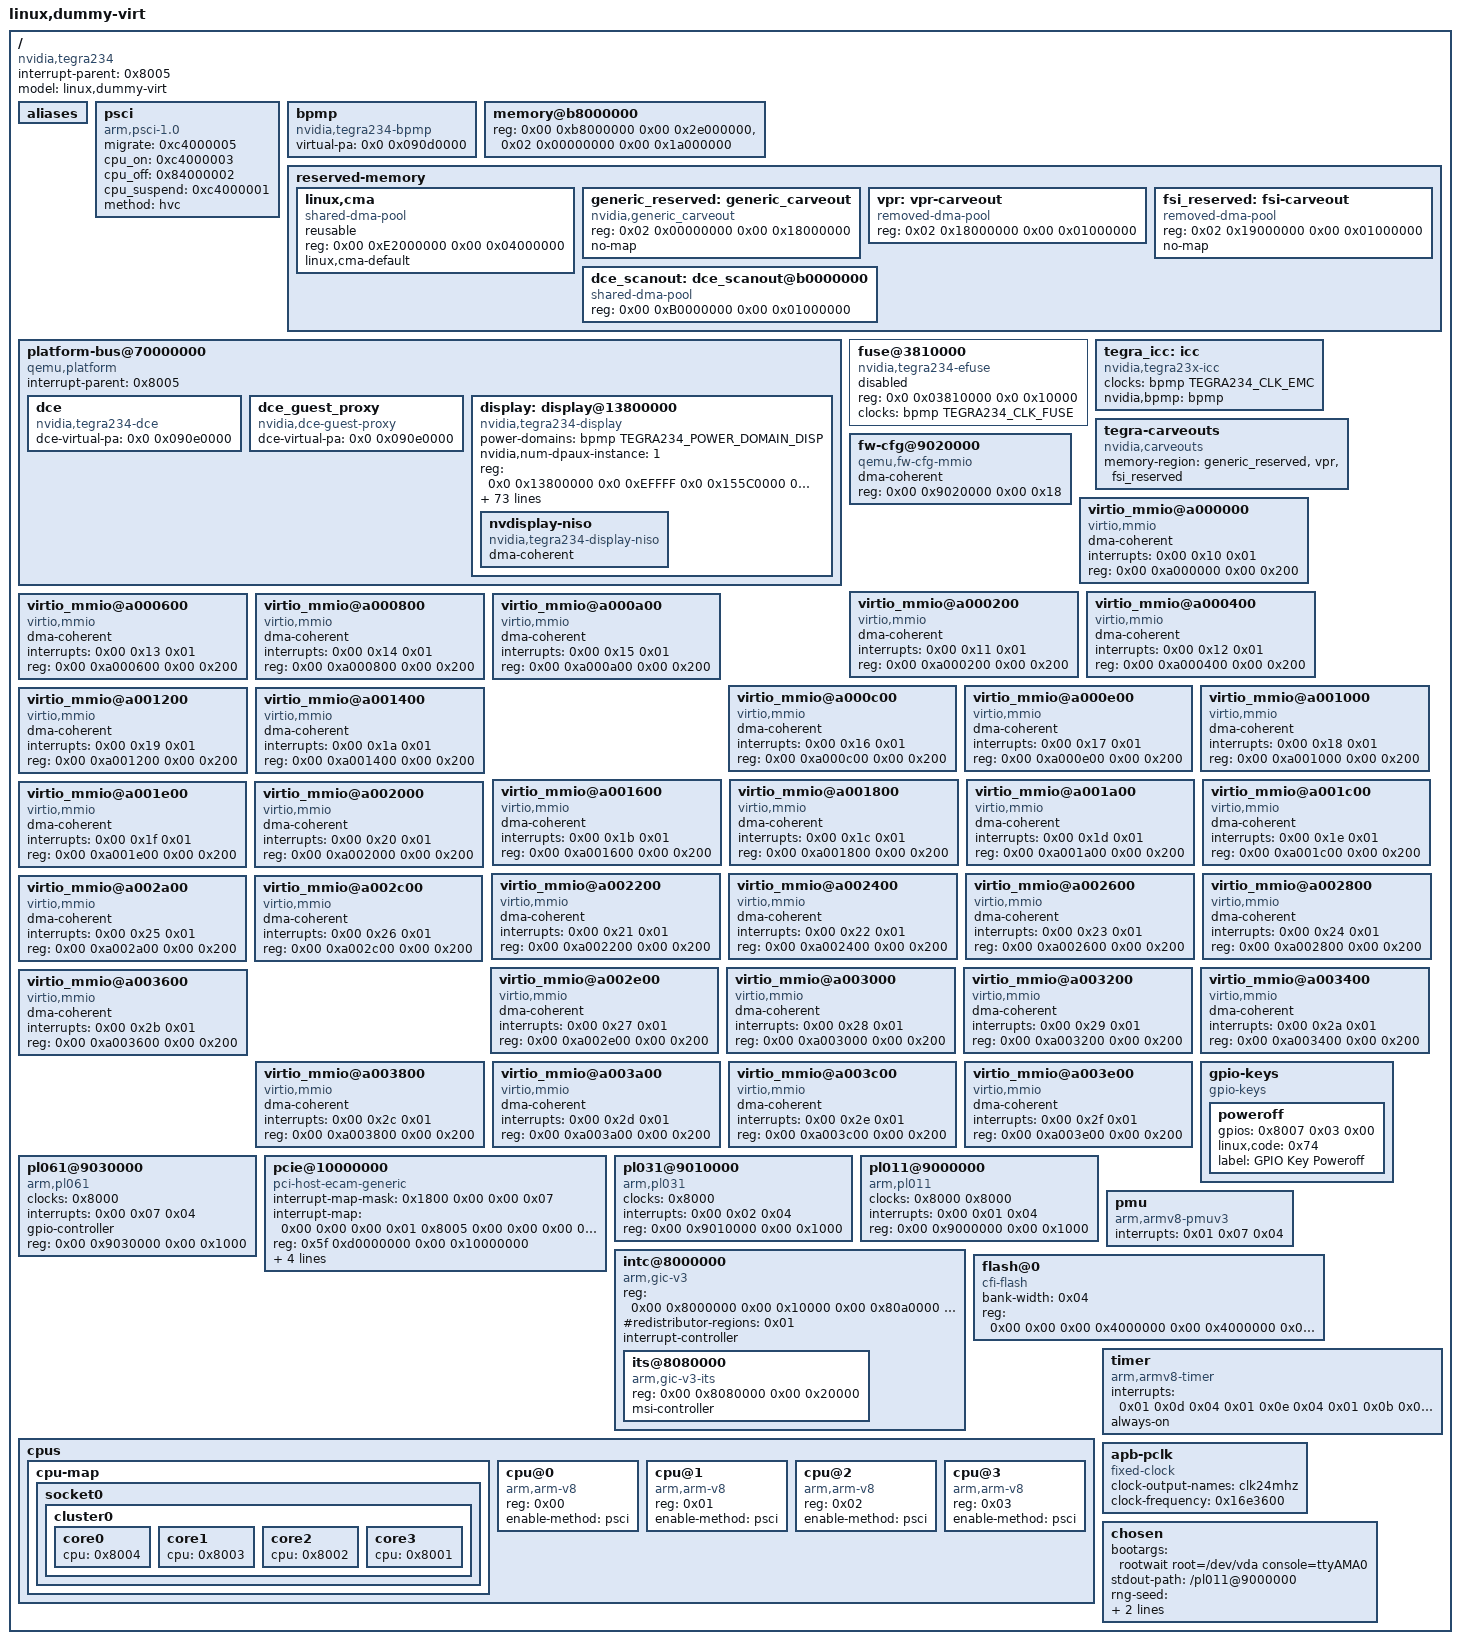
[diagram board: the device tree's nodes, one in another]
// SPDX-License-Identifier: GPL-2.0-only
// SPDX-FileCopyrightText: Copyright (c) 2023, NVIDIA CORPORATION & AFFILIATES.  All rights reserved.
//
// disp-vm guest DTS: display-only, no host1x, no gpu. Companion to
// tegra234-gpuvm.dts (compute-with-host1x mode) for the concurrent two-VM
// build (experiment/orin-two-vm-host1x). Owns exactly 3 physical devices
// (scanout_p, disp_caps_pt, disp_chan_pt), all already declared+reserved by
// gpu_passthrough_overlay.dts. Unlike the GPU VM, general guest RAM
// (memory@80000000) is plain QEMU -m emulated RAM -- no vm_cma_p carveout is
// claimed here, so there is no host-PA collision with the GPU VM's own
// bank1 at the same GPA range (each QEMU process has its own guest-physical
// address space). Only the scanout carveout is a real 1:1 GPA=HPA mapping.

#include <dt-bindings/clock/tegra234-clock.h>
#include <dt-bindings/reset/tegra234-reset.h>
#include <dt-bindings/mailbox/tegra186-hsp.h>
#include <dt-bindings/memory/tegra234-mc.h>
#include <dt-bindings/interrupt-controller/irq.h>
#include <dt-bindings/interrupt-controller/arm-gic.h>
#include <dt-bindings/interrupt/tegra234-irq.h>
#include <dt-bindings/gpio/tegra234-gpio.h>
#include <dt-bindings/p2u/tegra234-p2u.h>
#include <dt-bindings/power/tegra234-powergate.h>
#include <dt-bindings/pinctrl/pinctrl-tegra.h>

/dts-v1/;


/ {
	interrupt-parent = <0x8005>;
	model = "linux,dummy-virt";
	#size-cells = <0x02>;
	#address-cells = <0x02>;

	// Some drivers need that the root node has this compatible property
	compatible = "nvidia,tegra234";

	// No host1x alias: disp-vm never claims physical host1x (that stays
	// with the GPU VM as host1x owner).
	aliases {
	};

	psci {
		migrate = <0xc4000005>;
		cpu_on = <0xc4000003>;
		cpu_off = <0x84000002>;
		cpu_suspend = <0xc4000001>;
		method = "hvc";
		compatible = "arm,psci-1.0\0arm,psci-0.2\0arm,psci";
	};

	bpmp: bpmp {
		compatible = "nvidia,tegra234-bpmp", "nvidia,tegra186-bpmp";
		// Must match QEMU's VIRT_NVIDIA_BPMP_GUEST base (hw/arm/virt.c).
		virtual-pa = <0x0 0x090d0000>;
		#clock-cells = <1>;
		#reset-cells = <1>;
		#power-domain-cells = <1>;
		status = "okay";
	};

	// Plain QEMU -m emulated RAM (no 1:1 host carveout backs this bank):
	// bank1 only, 0x80000000..0xb0000000 (768MB). No GPU VRAM bank2 (no
	// GPU here). The scanout carveout at 0xb0000000 (below) is a SEPARATE
	// 1:1 vfio mapping, outside this bank.
	// disp-vm guest RAM = 1:1 GPA=HPA carveout (dispram_p@0x200000000, 1.125GB),
	// exactly like gpu-vm's vm_cma. QEMU -m does not reliably back the guest in
	// this tegra passthrough setup (the virt -m base != the DTB memory@), so RAM
	// comes from a real reserved host carveout mapped 1:1 via vfio mmio-base.
	// 0xb8000000..0x100000000 sits between disp-vm's scanout (0xb0..0xb8) and
	// gpu-vm's vram (0x100000000+), disjoint from every gpu-vm carveout.
	// Split RAM: LOW bank (0xb8000000..0xe6000000, 736MB = 672MB normal + 64MB CMA)
	// holds the kernel/initrd + working set. HIGH bank (0x200000000..0x21a000000,
	// 416MB) holds the GPU-style carveouts (generic/vpr/fsi), keeping the low bank
	// at the proven 672MB normal RAM. DMA32 hole 0xe6000000..0x100000000 left to
	// the host for PCIe MSI / WLAN.
	memory@b8000000 {
		reg = <0x00 0xb8000000 0x00 0x2e000000>,
		      <0x02 0x00000000 0x00 0x1a000000>;
		device_type = "memory";
	};

	reserved-memory {
		#address-cells = <2>;
		#size-cells = <2>;
		ranges;

		// All carveouts RELOCATED into disp-vm's backed RAM (dispram
		// 0xb8000000..0x100000000). The old 0x8x addresses were gpu-vm's bank1
		// region (0x80..0xb0) -- unbacked for disp-vm and overlapping the GPU
		// VM. Here they sit in disp-vm's own carveout RAM, leaving 0xb8000000..
		// carveouts live in the high dispram RAM (0x200000000..0x248000000),
		// leaving 0x200000000..0x220000000 (512MB) free kernel RAM (swiotlb fits)
		// + a 160MB tail. All backed by dispram_p; below-4GB DMA32 host RAM is
		// left untouched so PCIe MSI works.
		// CMA in the LOW bank (backed, cma-default) for dumb buffers.
		linux,cma {
			compatible = "shared-dma-pool";
			reusable;
			reg = <0x00 0xE2000000 0x00 0x04000000>; // 64MB @ 0xe2000000 (low bank top)
			linux,cma-default;
			status = "okay";
		};

		// GPU-style carveouts in the HIGH bank (0x200000000..0x21a000000).
		generic_reserved: generic_carveout {
			compatible = "nvidia,generic_carveout";
			reg = <0x02 0x00000000 0x00 0x18000000>; // 384MB @ 0x200000000..0x218000000
			no-map;
			status = "okay";
		};

		vpr: vpr-carveout {
			compatible = "removed-dma-pool";
			reg = <0x02 0x18000000 0x00 0x01000000>; // 16MB @ 0x218000000
			status = "okay";
		};

		fsi_reserved: fsi-carveout {
			compatible = "removed-dma-pool";
			reg = <0x02 0x19000000 0x00 0x01000000>; // 16MB @ 0x219000000
			no-map;
			status = "okay";
		};

		// 1:1 GPA=HPA scanout carveout. nvdisplay allocates the scanout
		// surface here; the host-owned DCE R5 DMAs it at the same
		// physical address. Backed 1:1 by scanout_p in
		// gpu_passthrough_overlay.dts (host removed-dma-pool + vfio
		// mmio-base=0xb0000000, already declared for the GPU VM and
		// reused here -- disp-vm is the sole owner in compute-with-host1x
		// mode, where the GPU VM drops its own scanout claim).
		// NOTE: sits OUTSIDE the memory@ bank1 above (which ends exactly
		// at 0xb0000000) -- validated on hardware as a follow-up gate
		// (Step 2 is build-only; see task handoff).
		dce_scanout: dce_scanout@b0000000 {
			// NOT reusable: this carveout is OUTSIDE every guest RAM bank
			// (bank1 ends exactly at 0xb0000000). "reusable" would make it CMA,
			// and cma_init_reserved_areas walks pfn_valid(0xb0000) -> faults on
			// out-of-System-RAM pages -> deterministic early kill-init. Plain
			// shared-dma-pool = dedicated coherent DMA pool (no CMA pfn walk);
			// dma_alloc_coherent still returns 0xb0000000-range scanout addrs.
			compatible = "shared-dma-pool";
			reg = <0x00 0xB0000000 0x00 0x01000000>; // 16MB (rest unclaimed)
			status = "okay";
		};
	};


	platform-bus@70000000 {
		interrupt-parent = <0x8005>;

		// QEMU does not map 1:1 the platform devices, so we have to define
		// the address translation here. Only display + dce need it (no
		// gpu/host1x/vic/nvdec/nvjpg on this VM).
		ranges = <0x00 0x13800000 0x00 0x66200000 0x00 0x000EFFFF>,     // display region 0
			 <0x00 0x155C0000 0x00 0x660e0000 0x00 0x0000FFFF>,     // display region 1 (dpaux0)
			 <0x00 0x0242c000 0x00 0x66001000 0x00 0x00001000>,     // display region 2 (hdacodec)
			 <0x00 0x03990000 0x00 0x660f0000 0x00 0x00010000>,     // display region 3 (mipical)
			 <0x00 0x0d800000 0x00 0x66800000 0x00 0x00800000>;     // dce region 0

		#address-cells = <0x02>;
		#size-cells = <0x02>;
		compatible = "qemu,platform\0simple-bus";

		dce {
			compatible = "nvidia,tegra234-dce";
			dce-virtual-pa = <0x0 0x090e0000>;
			status = "okay";
		};

		// The dce-guest-proxy .ko binds this node, ioremaps dce-virtual-pa
		// and installs tegra_dce_ipc_send_redirect so tegra-dce's client
		// sends are relayed through the shared window to the host DCE.
		dce_guest_proxy {
			compatible = "nvidia,dce-guest-proxy";
			dce-virtual-pa = <0x0 0x090e0000>;
			status = "okay";
		};
		display: display@13800000 {
			compatible = "nvidia,tegra234-display";
			power-domains = <&bpmp TEGRA234_POWER_DOMAIN_DISP>;
			nvidia,num-dpaux-instance = <1>;
			reg-names = "nvdisplay", "dpaux0", "hdacodec", "mipical";
			reg = <0x0 0x13800000 0x0 0xEFFFF    /* nvdisplay */
				0x0 0x155C0000 0x0 0xFFFF     /* dpaux0 */
				0x0 0x0242c000 0x0 0x1000     /* hdacodec */
				0x0 0x03990000 0x0 0x10000>;  /* mipical */
			interrupt-names = "nvdisplay", "dpaux0", "hdacodec";
			interrupts = <0 128 4
				0 129 4
				0 130 4>;
			nvidia,bpmp = <&bpmp>;
			clocks = <&bpmp TEGRA234_CLK_HUB>,
				<&bpmp TEGRA234_CLK_DISP>,
				<&bpmp TEGRA234_CLK_NVDISPLAY_P0>,
				<&bpmp TEGRA234_CLK_NVDISPLAY_P1>,
				<&bpmp TEGRA234_CLK_DPAUX>,
				<&bpmp TEGRA234_CLK_FUSE>,
				<&bpmp TEGRA234_CLK_DSIPLL_VCO>,
				<&bpmp TEGRA234_CLK_DSIPLL_CLKOUTPN>,
				<&bpmp TEGRA234_CLK_DSIPLL_CLKOUTA>,
				<&bpmp TEGRA234_CLK_SPPLL0_VCO>,
				<&bpmp TEGRA234_CLK_SPPLL0_CLKOUTPN>,
				<&bpmp TEGRA234_CLK_SPPLL0_CLKOUTA>,
				<&bpmp TEGRA234_CLK_SPPLL0_CLKOUTB>,
				<&bpmp TEGRA234_CLK_SPPLL0_DIV10>,
				<&bpmp TEGRA234_CLK_SPPLL0_DIV25>,
				<&bpmp TEGRA234_CLK_SPPLL0_DIV27PN>,
				<&bpmp TEGRA234_CLK_SPPLL1_VCO>,
				<&bpmp TEGRA234_CLK_SPPLL1_CLKOUTPN>,
				<&bpmp TEGRA234_CLK_SPPLL1_DIV27PN>,
				<&bpmp TEGRA234_CLK_VPLL0_REF>,
				<&bpmp TEGRA234_CLK_VPLL0>,
				<&bpmp TEGRA234_CLK_VPLL1>,
				<&bpmp TEGRA234_CLK_NVDISPLAY_P0_REF>,
				<&bpmp TEGRA234_CLK_RG0>,
				<&bpmp TEGRA234_CLK_RG1>,
				<&bpmp TEGRA234_CLK_DISPPLL>,
				<&bpmp TEGRA234_CLK_DISPHUBPLL>,
				<&bpmp TEGRA234_CLK_DSI_LP>,
				<&bpmp TEGRA234_CLK_DSI_CORE>,
				<&bpmp TEGRA234_CLK_DSI_PIXEL>,
				<&bpmp TEGRA234_CLK_PRE_SOR0>,
				<&bpmp TEGRA234_CLK_PRE_SOR1>,
				<&bpmp TEGRA234_CLK_DP_LINK_REF>,
				<&bpmp TEGRA234_CLK_SOR_LINKA_INPUT>,
				<&bpmp TEGRA234_CLK_SOR_LINKA_AFIFO>,
				<&bpmp TEGRA234_CLK_SOR_LINKA_AFIFO_M>,
				<&bpmp TEGRA234_CLK_RG0_M>,
				<&bpmp TEGRA234_CLK_RG1_M>,
				<&bpmp TEGRA234_CLK_SOR0_M>,
				<&bpmp TEGRA234_CLK_SOR1_M>,
				<&bpmp TEGRA234_CLK_PLLHUB>,
				<&bpmp TEGRA234_CLK_SOR0>,
				<&bpmp TEGRA234_CLK_SOR1>,
				<&bpmp TEGRA234_CLK_SOR_PAD_INPUT>,
				<&bpmp TEGRA234_CLK_PRE_SF0>,
				<&bpmp TEGRA234_CLK_SF0>,
				<&bpmp TEGRA234_CLK_SF1>,
				<&bpmp TEGRA234_CLK_DSI_PAD_INPUT>,
				<&bpmp TEGRA234_CLK_PRE_SOR0_REF>,
				<&bpmp TEGRA234_CLK_PRE_SOR1_REF>,
				<&bpmp TEGRA234_CLK_SOR0_PLL_REF>,
				<&bpmp TEGRA234_CLK_SOR1_PLL_REF>,
				<&bpmp TEGRA234_CLK_SOR0_REF>,
				<&bpmp TEGRA234_CLK_SOR1_REF>,
				<&bpmp TEGRA234_CLK_OSC>,
				<&bpmp TEGRA234_CLK_DSC>,
				<&bpmp TEGRA234_CLK_MAUD>,
				<&bpmp TEGRA234_CLK_AZA_2XBIT>,
				<&bpmp TEGRA234_CLK_AZA_BIT>,
				<&bpmp TEGRA234_CLK_MIPI_CAL>,
				<&bpmp TEGRA234_CLK_UART_FST_MIPI_CAL>,
				<&bpmp TEGRA234_CLK_SOR0_DIV>;
			clock-names = "nvdisplayhub_clk",
				"nvdisplay_disp_clk",
				"nvdisplay_p0_clk",
				"nvdisplay_p1_clk",
				"dpaux0_clk",
				"fuse_clk",
				"dsipll_vco_clk",
				"dsipll_clkoutpn_clk",
				"dsipll_clkouta_clk",
				"sppll0_vco_clk",
				"sppll0_clkoutpn_clk",
				"sppll0_clkouta_clk",
				"sppll0_clkoutb_clk",
				"sppll0_div10_clk",
				"sppll0_div25_clk",
				"sppll0_div27_clk",
				"sppll1_vco_clk",
				"sppll1_clkoutpn_clk",
				"sppll1_div27_clk",
				"vpll0_ref_clk",
				"vpll0_clk",
				"vpll1_clk",
				"nvdisplay_p0_ref_clk",
				"rg0_clk",
				"rg1_clk",
				"disppll_clk",
				"disphubpll_clk",
				"dsi_lp_clk",
				"dsi_core_clk",
				"dsi_pixel_clk",
				"pre_sor0_clk",
				"pre_sor1_clk",
				"dp_link_ref_clk",
				"sor_linka_input_clk",
				"sor_linka_afifo_clk",
				"sor_linka_afifo_m_clk",
				"rg0_m_clk",
				"rg1_m_clk",
				"sor0_m_clk",
				"sor1_m_clk",
				"pllhub_clk",
				"sor0_clk",
				"sor1_clk",
				"sor_pad_input_clk",
				"pre_sf0_clk",
				"sf0_clk",
				"sf1_clk",
				"dsi_pad_input_clk",
				"pre_sor0_ref_clk",
				"pre_sor1_ref_clk",
				"sor0_ref_pll_clk",
				"sor1_ref_pll_clk",
				"sor0_ref_clk",
				"sor1_ref_clk",
				"osc_clk",
				"dsc_clk",
				"maud_clk",
				"aza_2xbit_clk",
				"aza_bit_clk",
				"mipi_cal_clk",
				"uart_fst_mipi_cal_clk",
				"sor0_div_clk";
			resets = <&bpmp TEGRA234_RESET_NVDISPLAY>,
				<&bpmp TEGRA234_RESET_DPAUX>,
				<&bpmp TEGRA234_RESET_DSI_CORE>,
				<&bpmp TEGRA234_RESET_MIPI_CAL>;
			reset-names = "nvdisplay_reset",
				"dpaux0_reset",
				"dsi_core_reset",
				"mipi_cal_reset";
			// hdcp_enabled OMITTED: HDCP handshake invokes the host OP-TEE HDCP/display TA whose supplicant (optee_supp_thrd_req) UAF corrupts the host heap (slub_debug-confirmed); also HPD-glitches DP->HDMI adapters on R36.5.0. Not needed for a plain desktop.
			status = "okay";
			// Scanout surface is allocated from the 1:1 GPA=HPA carveout so
			// the host-owned DCE R5 can DMA it at the same physical address
			// (patch 0003 forces page phys=bus for this device).
			memory-region = <&dce_scanout>;
			nvidia,disp-sw-soc-chip-id = <0x2350>;
	// 		interconnects = <&mc TEGRA234_MEMORY_CLIENT_NVDISPLAYR &emc>,
	// 			      <&mc TEGRA234_MEMORY_CLIENT_NVDISPLAYR1 &emc>;
	// 		interconnect-names = "dma-mem", "read-1";
			//iommus = <&smmu_iso TEGRA234_SID_ISO_NVDISPLAY>;
			non-coherent;

			/* DCB 94.0B.00.00.20 extracted verbatim from the composed host
			 * DTB (tegra234-p3737-0000+p3701-0000-nv.dtb) -- the guest RM
			 * must build display routing from the SAME board topology the
			 * host-owned DCE R5 drives; the previous blob was 94.0B.00.00.21
			 * from a different tree (foreign SOR/connector routing). */
			nvidia,dcb-image = [
				55 aa 16 00 00 37 34 30 30 e9 4c 19 77 cc 56 49
				44 45 4f 20 0d 00 00 00 70 01 00 00 00 00 49 42
				4d 20 56 47 41 20 43 6f 6d 70 61 74 69 62 6c 65
				01 00 00 00 10 00 c7 17 31 30 2f 32 36 2f 32 31
				00 00 00 00 00 00 00 00 21 18 50 00 f1 2a 00 00
				50 4d 49 44 00 00 00 00 00 00 00 a0 00 b0 00 b8
				00 c0 00 0e 47 41 31 30 42 20 56 47 41 20 42 49
				4f 53 0d 0a 00 00 00 00 00 00 00 00 00 00 00 00
				00 00 00 00 00 00 00 00 00 00 00 00 00 00 00 00
				00 00 00 00 00 00 00 00 00 00 00 00 00 00 00 00
				00 00 00 00 00 00 00 00 00 00 00 00 00 00 00 00
				00 00 00 00 00 56 65 72 73 69 6f 6e 20 39 34 2e
				30 42 2e 30 30 2e 30 30 2e 32 30 20 0d 0a 00 43
				6f 70 79 72 69 67 68 74 20 28 43 29 20 31 39 39
				36 2d 32 30 32 31 20 4e 56 49 44 49 41 20 43 6f
				72 70 2e 0d 0a 00 00 00 ff ff 00 00 00 00 ff ff
				47 50 55 20 42 6f 61 72 64 00 00 00 00 00 00 00
				00 00 00 00 00 00 00 00 00 00 00 00 00 00 00 00
				00 00 00 43 68 69 70 20 52 65 76 20 20 20 00 00
				00 00 00 00 00 00 00 ba 91 98 96 91 9a 9a 8d 96
				91 98 df ad 9a 93 9a 9e 8c 9a df d2 df b1 90 8b
				df b9 90 8d df af 8d 90 9b 8a 9c 8b 96 90 91 df
				aa 8c 9a f2 f5 ff 00 00 00 00 00 00 00 00 00 00
				50 43 49 52 de 10 94 22 00 00 18 00 00 00 00 03
				16 00 01 00 00 80 00 00 2e 8b c0 2e 8b c0 8b c0
				4e 50 44 45 01 01 14 00 16 00 00 01 00 00 00 00
				00 00 00 00 00 00 00 00 00 00 00 00 00 00 00 00
				ff b8 42 49 54 00 00 01 0c 06 12 45 32 01 04 00
				38 02 42 02 25 00 44 02 43 02 2c 00 69 02 44 01
				04 00 95 02 49 01 24 00 99 02 4d 02 29 00 bd 02
				4e 00 00 00 00 00 50 02 e8 00 e6 02 53 02 18 00
				ce 03 54 01 02 00 e6 03 55 01 05 00 ec 03 56 01
				06 00 f1 03 78 01 08 00 f7 03 64 01 02 00 ff 03
				70 02 04 00 01 04 75 01 11 00 05 04 69 02 6e 00
				18 04 45 01 04 00 e8 03 00 00 86 04 86 04 fe 20
				00 21 f0 2a 00 00 00 00 00 00 00 00 00 00 00 00
				00 00 00 00 00 00 0b 94 20 00 00 00 00 00 a8 07
				00 00 00 00 00 00 00 00 02 00 5c 5c 28 02 00 00
				3c 02 04 00 10 00 00 00 00 f5 0e 00 00 00 00 00
				00 35 44 00 00 c7 2d 00 00 00 00 00 00 00 00 00
				00 00 00 00 00 72 30 00 00 e1 44 00 00 1f 45 00
				00 46 45 00 00 00 00 00 00 da 04 00 00 00 00 de
				04 00 00 4a 08 de 04 26 2a 4a 08 28 2a 86 04 ef
				09 14 21 d4 09 d7 20 28 2a 90 00 ab 21 01 4c 08
				3a 09 f0 43 00 00 fa 43 00 00 03 10 00 00 00 21
				00 00 0c 21 00 00 50 4a 00 00 00 00 00 00 00 00
				00 00 00 00 00 00 d5 33 00 00 bb 36 00 00 00 00
				00 00 00 00 00 00 00 00 00 00 00 00 00 00 00 00
				00 00 00 00 00 00 af 3c 00 00 00 00 00 00 e9 3c
				00 00 0e 43 00 00 00 00 00 00 00 00 00 00 df 33
				00 00 2e 3d 00 00 9c 43 00 00 ad 36 00 00 00 00
				00 00 00 00 00 00 be 43 00 00 00 00 00 00 00 00
				00 00 00 00 00 00 00 00 00 00 00 00 00 00 45 0b
				00 00 c1 0a 00 00 5b 0b 00 00 11 3c 00 00 17 3c
				00 00 1c 3c 00 00 20 3c 00 00 2a 3c 00 00 31 3c
				00 00 3f 3c 00 00 81 3c 00 00 00 00 00 00 00 00
				00 00 92 3c 00 00 ec 45 00 00 92 47 00 00 07 48
				00 00 8d 49 00 00 7c 4b 00 00 b8 4b 00 00 e2 49
				00 00 98 3c 00 00 79 3c 00 00 00 00 00 00 00 00
				00 00 00 00 00 00 e8 4d 00 00 9c 3c 00 00 a5 3c
				00 00 00 00 00 00 00 00 00 00 00 00 00 00 64 00
				50 b5 00 19 cf 00 28 75 0e 14 89 0e 23 00 01 23
				23 01 14 ac 0e 28 18 11 00 00 00 00 d4 0e 01 00
				00 f1 0d c3 0c 00 00 00 00 01 01 00 00 00 00 f4
				1c 2d 4e 00 00 00 00 00 00 00 00 00 00 00 00 00
				00 00 92 2d 00 00 00 00 00 00 0b 94 20 00 00 20
				92 d2 01 58 03 00 00 31 30 2f 32 36 2f 32 31 00
				00 00 00 00 00 00 00 00 00 00 00 21 01 10 00 00
				00 80 01 00 00 00 00 00 30 30 30 30 30 30 30 30
				30 30 30 30 00 00 00 00 00 00 00 00 03 42 00 00
				b9 78 8f 47 ad 04 4f 3d bf 01 4c 10 55 04 be ee
				54 33 00 00 00 00 00 00 c5 4c 00 00 00 00 00 00
				00 00 93 4e 00 00 01 00 10 00 bf 09 30 00 02 00
				94 22 00 00 00 00 01 00 44 00 6b 09 00 00 86 04
				00 00 3a 09 00 00 de 04 00 00 00 00 00 00 4a 08
				00 00 5c 08 00 00 45 0b 00 00 c1 0a 00 00 5b 0b
				00 00 71 0b 00 00 f1 0d 00 00 c3 0c 00 00 00 00
				00 00 00 00 00 00 00 00 00 00 3c 21 00 00 30 c0
				61 40 00 00 00 10 00 00 00 00 08 23 61 00 80 00
				00 00 80 00 00 00 88 23 61 00 80 00 00 00 80 00
				00 00 08 24 61 00 80 00 00 00 80 00 00 00 88 24
				61 00 80 00 00 00 80 00 00 00 08 25 61 00 80 00
				00 00 80 00 00 00 88 25 61 00 80 00 00 00 80 00
				00 00 08 26 61 00 80 00 00 00 80 00 00 00 00 2a
				13 00 00 00 04 00 00 00 04 00 00 2a 13 00 00 00
				01 00 00 00 01 00 00 6e 13 00 00 00 04 00 00 00
				04 00 00 6e 13 00 00 00 01 00 00 00 01 00 4c 00
				12 00 3f 00 00 00 00 00 00 00 0c 24 02 00 01 00
				00 00 00 00 00 00 e4 05 02 00 7c 00 00 00 00 00
				00 00 e4 05 02 00 7c 00 00 00 18 00 00 00 e4 05
				02 00 7c 00 00 00 0c 00 00 00 e4 05 02 00 7c 00
				00 00 04 00 00 00 e4 05 02 00 7c 00 00 00 08 00
				00 00 e4 05 02 00 7c 00 00 00 14 00 00 00 20 0e
				9a 00 00 00 02 00 00 00 02 00 00 0e 9a 00 00 00
				02 00 00 00 02 00 00 0e 9a 00 01 00 00 00 01 00
				00 00 34 c0 61 40 00 00 00 80 00 00 00 00 00 0c
				82 00 ff ff ff ff 00 00 00 00 00 0c 82 00 01 00
				00 00 00 00 00 00 00 0c 82 00 02 00 00 00 00 00
				00 00 00 0c 82 00 04 00 00 00 00 00 00 00 00 0c
				82 00 08 00 00 00 00 00 00 00 00 0c 82 00 10 00
				00 00 00 00 00 00 00 0c 82 00 20 00 00 00 00 00
				00 00 90 02 82 00 01 00 00 00 00 00 00 00 88 02
				82 00 ff 00 00 00 00 00 00 00 c0 04 82 00 07 00
				00 00 00 00 00 00 00 0a 00 00 00 00 f0 1f 00 00
				00 00 88 80 08 00 00 00 0f 00 00 00 01 00 40 c0
				08 00 00 00 0c 00 00 00 0c 00 40 c0 08 00 1f 00
				00 00 00 00 00 00 00 0a 00 00 00 00 f0 1f 00 00
				00 00 74 09 9a 00 0f 00 00 00 00 00 00 00 e8 73
				13 00 01 00 00 00 01 00 00 00 0c 06 9a 00 40 00
				00 00 40 00 00 00 64 00 12 00 40 00 00 00 40 00
				00 00 04 14 00 00 04 00 00 00 00 00 00 00 04 14
				00 00 08 00 00 00 08 00 00 00 14 38 82 00 00 00
				01 00 00 00 01 00 00 0a 00 00 00 00 f0 1f 00 00
				00 00 0c 14 00 00 01 00 00 00 01 00 00 00 0c 14
				00 00 02 00 00 00 01 00 00 00 88 54 62 00 00 00
				01 00 00 00 00 00 88 54 62 00 00 00 02 00 00 00
				00 00 88 54 62 00 00 00 04 00 00 00 00 00 9c 8b
				11 00 00 00 00 80 00 00 00 00 14 0c 82 00 01 00
				00 00 00 00 00 00 14 0c 82 00 02 00 00 00 00 00
				00 00 14 0c 82 00 04 00 00 00 00 00 00 00 14 0c
				82 00 08 00 00 00 00 00 00 00 14 0c 82 00 10 00
				00 00 00 00 00 00 14 0c 82 00 20 00 00 00 00 00
				00 00 9c 8b 11 00 00 00 00 80 00 00 00 00 10 01
				82 00 01 00 00 00 00 00 00 00 d4 06 82 00 ff 03
				00 00 00 00 00 00 14 0c 82 00 3f 00 00 00 01 00
				00 00 00 14 00 00 02 00 00 00 00 00 00 00 44 c1
				61 60 01 00 00 00 01 00 00 00 20 87 08 00 04 00
				00 00 00 00 00 00 40 00 82 00 01 00 00 00 00 00
				00 00 54 9b 41 00 ff 00 00 00 00 00 00 00 68 9b
				41 00 03 00 00 00 00 00 00 00 40 80 11 00 02 00
				00 00 00 00 00 00 04 0c 82 00 01 00 00 00 00 00
				00 00 04 14 00 00 00 04 00 00 00 00 00 00 34 04
				82 00 01 00 00 00 00 00 00 00 4c 08 00 01 02 03
				04 05 06 07 00 01 02 03 04 05 06 07 41 06 24 06
				00 00 00 07 00 02 bf 00 01 51 00 04 bf 00 02 5e
				00 01 bf 00 03 52 00 03 bf 00 84 19 00 00 4f 00
				85 7b 59 98 4f 00 06 ff 00 00 4f 00 07 ff 00 00
				ef 00 08 ff 00 00 ef 00 09 ff 00 00 ef 00 0a ff
				00 00 ef 00 0b ff 00 00 ef 00 0c ff 00 00 ef 00
				0d ff 00 00 ef 00 0e ff 00 00 ef 00 0f ff 00 00
				ef 00 10 42 50 11 e4 00 11 41 42 0b e2 00 12 40
				41 0a e1 00 13 70 51 12 e5 00 14 ff 00 00 ef 00
				15 ff 00 00 ef 00 16 ff 00 00 ef 00 17 ff 00 00
				ef 00 18 ff 00 00 ef 00 19 ff 00 00 ef 00 1a ff
				00 00 ef 00 1b ff 00 00 ef 00 1c ff 00 00 ef 00
				1d ff 00 00 ef 00 1e ff 00 00 ef 00 1f ff 00 00
				ef 00 00 ff 00 00 0f 00 00 ff 00 00 0f 00 00 ff
				00 00 0f 00 00 ff 00 00 0f 00 10 07 16 10 00 a1
				0a 01 f0 10 03 00 00 00 00 ff ff ff 00 ff ff 00
				10 00 00 00 00 00 00 1f 01 00 00 00 00 00 00 ff
				ff ff 00 ff ff 00 10 00 00 00 00 00 00 2f 02 00
				00 00 00 00 00 ff ff ff 00 ff ff 00 10 00 00 00
				00 00 00 3f 03 00 00 00 00 00 00 ff ff ff 00 ff
				ff 00 10 00 00 00 00 00 00 4f 04 00 00 00 00 00
				00 ff ff ff 00 ff ff 00 10 00 00 00 00 00 00 5f
				05 00 00 00 00 00 00 ff ff ff 00 ff ff 00 10 00
				00 00 00 00 00 6f 06 00 00 00 00 00 00 ff ff ff
				00 ff ff 00 10 00 00 00 00 00 00 7f 07 00 00 00
				00 00 00 ff ff ff 00 ff ff 00 10 00 00 00 00 00
				00 8f 00 00 00 00 00 00 00 ff ff ff 00 ff ff 00
				10 00 00 00 00 00 00 9f 01 00 00 00 00 00 00 ff
				ff ff 00 ff ff 00 10 00 00 00 00 00 00 af 02 00
				00 00 00 00 00 ff ff ff 00 ff ff 00 10 00 00 00
				00 00 00 bf 03 00 00 00 00 00 00 ff ff ff 00 ff
				ff 00 10 00 00 00 00 00 00 cf 04 00 00 00 00 00
				00 ff ff ff 00 ff ff 00 10 00 00 00 00 00 00 df
				05 00 00 00 00 00 00 ff ff ff 00 ff ff 00 10 00
				00 00 00 00 00 ef 06 00 00 00 00 00 00 ff ff ff
				00 ff ff 00 10 00 00 00 00 00 00 ff 07 00 00 00
				00 00 00 ff ff ff 00 ff ff 00 10 00 00 00 00 00
				00 00 01 02 03 04 05 06 07 08 09 0a 0b 0c 0d 0e
				0f 10 11 12 13 14 15 16 17 18 19 1a 1b 1c 1d 1e
				1f 10 04 20 04 00 00 80 00 b8 4c 0a ff e0 93 04
				00 20 d6 13 00 e0 93 04 01 20 d6 13 00 ff 00 00
				00 00 00 00 00 00 00 00 00 00 00 00 ff 00 00 00
				00 00 00 00 00 00 00 00 01 00 00 00 00 ff 00 00
				00 00 00 00 00 00 00 00 00 00 00 00 ff 00 00 00
				00 00 00 00 00 00 00 00 01 00 00 00 00 ff 00 00
				00 00 00 00 00 00 00 00 00 00 00 00 ff 00 00 00
				00 00 00 00 00 00 00 00 01 00 00 00 00 ff 00 00
				00 00 00 00 00 20 05 11 01 00 00 35 0c 00 ff ff
				ff ff ff ff ff ff ff 00 00 00 00 10 05 11 01 00
				00 00 00 ff ff 00 00 00 00 00 00 00 00 00 00 00
				00 30 08 10 01 14 01 15 0e 00 00 00 00 00 00 00
				00 00 00 00 00 00 00 00 00 00 00 00 00 00 00 00
				00 00 00 00 00 00 00 00 00 00 00 00 00 00 00 00
				00 00 00 00 00 00 00 00 00 00 00 00 00 00 00 00
				00 00 00 00 00 00 00 00 00 00 00 00 00 00 00 00
				00 00 00 00 00 00 00 00 00 00 00 00 00 00 00 00
				00 00 00 00 00 00 00 00 00 00 00 00 00 00 00 00
				00 00 00 00 00 00 00 00 00 00 00 00 00 00 00 00
				00 00 00 00 00 00 00 00 00 00 00 00 00 00 00 00
				00 00 00 00 00 00 00 00 00 00 00 00 00 00 00 00
				00 00 00 00 00 00 00 00 00 00 00 00 00 00 00 00
				00 00 00 00 00 00 00 00 00 00 00 00 00 00 00 00
				00 00 00 00 00 00 00 00 00 00 00 00 00 00 00 00
				00 00 00 00 00 00 00 00 00 00 00 00 00 00 00 00
				00 00 00 00 00 00 00 00 00 00 00 00 00 00 00 00
				00 00 00 00 00 00 00 00 00 00 00 00 00 00 00 00
				00 00 00 00 00 00 00 00 00 00 00 00 00 00 00 00
				00 00 00 00 00 00 00 00 00 00 00 00 00 00 00 00
				00 00 00 00 00 00 00 00 00 00 00 00 00 00 00 00
				00 00 00 00 00 00 00 00 00 00 00 00 00 00 00 00
				00 00 00 00 00 00 00 00 00 00 00 00 00 00 00 00
				00 00 00 10 0d 17 34 b0 8f 11 00 00 00 00 00 00
				00 00 00 34 a8 04 82 00 00 00 00 00 00 00 00 00
				34 a0 04 82 00 00 00 00 00 00 00 00 00 34 d4 02
				82 00 00 00 00 00 00 00 00 00 34 a4 04 82 00 00
				00 00 00 00 00 00 00 34 7c 14 00 00 00 00 00 00
				00 00 00 00 34 08 0e 82 00 00 00 00 00 00 00 00
				00 34 0c 0e 82 00 00 00 00 00 00 00 00 00 34 a8
				83 11 00 00 00 00 00 00 00 00 00 34 78 01 82 00
				00 00 00 00 00 00 00 00 34 78 01 82 00 00 00 00
				00 00 00 00 00 34 ac 04 82 00 00 00 00 00 00 00
				00 00 34 94 10 82 00 00 00 00 00 00 00 00 00 34
				88 10 82 00 00 00 00 00 00 00 00 00 34 8c 10 82
				00 00 00 00 00 00 00 00 00 34 90 10 82 00 00 00
				00 00 00 00 00 00 34 ac 83 11 00 00 00 00 00 00
				00 00 00 34 78 01 82 00 00 00 00 00 00 00 00 00
				34 d4 02 82 00 00 00 00 00 00 00 00 00 34 78 05
				82 00 00 00 00 00 00 00 00 00 34 b0 04 82 00 00
				00 00 00 00 00 00 00 34 78 01 82 00 00 00 00 00
				00 00 00 00 34 7c 07 82 00 00 00 00 00 00 00 00
				00 10 03 1b 05 80 00 07 60 05 08 40 08 09 60 0d
				0a 40 10 0d f0 17 0c e0 15 0e 60 18 0f 40 1c 10
				e0 23 15 80 24 16 26 29 17 60 2d 18 40 30 19 60
				35 1a 60 39 1b 60 3d 1d e0 43 1e a5 44 1f 60 49
				20 60 4d 21 60 51 22 fc 47 23 a0 58 24 66 59 25
				2c 5a 26 f2 5a ff 7d f4 ed 1f 18 7c a3 82 dc b6
				81 88 d5 6f da 00 00 00 00 00 00 00 00 00 00 00
				00 00 00 00 00 00 00 00 00 00 00 00 00 00 00 00
				00 00 00 00 00 4e 56 49 44 49 41 00 00 00 00 00
				00 00 00 00 00 00 00 00 00 4e 56 49 44 49 41 20
				43 6f 72 70 6f 72 61 74 69 6f 6e 00 00 00 00 00
				00 00 00 00 00 00 00 00 00 00 00 00 42 49 4f 53
				20 43 65 72 74 69 66 69 63 61 74 65 20 43 68 65
				63 6b 20 46 61 69 6c 65 64 21 21 21 0d 0a 00 00
				00 00 00 00 22 05 02 0e 0c 00 00 00 00 00 00 00
				00 00 00 00 00 00 00 00 00 00 00 00 00 00 00 00
				00 00 00 00 00 50 04 13 0e 07 95 01 95 01 d0 07
				a0 0f 1b 00 1b 00 0f 0f 32 ff 01 3f 08 95 01 95
				01 d0 07 a0 0f 1b 00 1b 00 0f 0f 32 ff 01 3f 0b
				95 01 95 01 d0 07 a0 0f 1b 00 1b 00 0f 0f 32 ff
				01 3f 04 e1 00 13 01 94 11 28 23 e1 00 13 01 01
				01 14 ff 01 02 0c 1b 00 1b 00 40 06 80 0c 1b 00
				1b 00 01 01 28 ff 01 3f 41 1b 00 1b 00 40 06 8c
				0a 1b 00 28 00 01 ff 28 ff 03 3f 42 1b 00 1b 00
				40 06 8c 0a 1b 00 28 00 01 ff 28 ff 03 3f 80 1b
				00 1b 00 20 03 54 06 1b 00 1b 00 01 01 14 ff 01
				3f 81 1b 00 1b 00 20 03 54 06 1b 00 1b 00 01 01
				14 ff 01 3f 82 1b 00 1b 00 20 03 54 06 1b 00 1b
				00 01 01 14 ff 01 3f 83 1b 00 1b 00 20 03 54 06
				1b 00 1b 00 01 01 14 ff 01 3f 0d 1b 00 1b 00 20
				03 54 06 1b 00 1b 00 01 01 14 ff 01 3f 0e 1b 00
				1b 00 e8 03 d0 07 0d 00 1b 00 01 ff 28 ff 01 1f
				0f 95 01 95 01 d0 07 a0 0f 1b 00 1b 00 0f 0f 32
				ff 01 3f 10 04 02 06 00 00 00 07 00 07 00 07 00
				07 00 07 10 05 04 10 04 0f 0f 0f 0f 2f 2f 2f 2f
				1c 1c 1c 1c 0f 46 40 00 0f 0f 0f 0f 2f 2f 2f 2f
				1d 1d 1d 1d 0f 46 40 00 0f 0f 0f 0f 2f 2f 2f 2f
				1e 1e 1e 1e 0f 46 40 00 0f 0f 0f 0f 2f 2f 2f 2f
				1f 1f 1f 1f 0f 46 40 00 0f 0f 0f 0f 2d 2d 2d 2d
				19 19 19 19 0f 46 40 00 0f 0f 0f 0f 2c 2c 2c 2c
				1b 1b 1b 1b 0f 46 40 00 0f 0f 0f 0f 2b 2b 2b 2b
				1d 1d 1d 1d 0f 46 40 00 0f 0f 0f 0f 2a 2a 2a 2a
				1f 1f 1f 1f 0f 46 40 00 0e 0e 0e 0e 29 29 29 29
				18 18 18 18 0f 46 40 00 0e 0e 0e 0e 28 28 28 28
				1a 1a 1a 1a 0f 46 40 00 0e 0e 0e 0e 27 27 27 27
				1c 1c 1c 1c 0f 46 40 00 0e 0e 0e 0e 26 26 26 26
				1e 1e 1e 1e 0f 46 40 00 0f 0f 0f 0f 2d 2d 2d 2d
				19 19 19 19 0f 46 40 00 0f 0f 0f 0f 2c 2c 2c 2c
				1b 1b 1b 1b 0f 46 40 00 0f 0f 0f 0f 2b 2b 2b 2b
				1d 1d 1d 1d 0f 46 40 00 0f 0f 0f 0f 2a 2a 2a 2a
				1f 1f 1f 1f 0f 46 40 00 20 19 04 00 00 50 32 74
				40 e8 80 e4 57 01 04 04 06 76 19 00 00 13 10 00
				00 49 11 00 00 47 12 00 00 45 13 00 00 43 14 00
				00 41 15 00 00 3f 16 00 00 10 08 0e 05 00 2c 04
				04 d1 84 00 00 00 00 0a 05 00 06 00 00 00 00 00
				38 3d 3e 3f 3a 00 00 00 00 05 05 05 05 00 00 00
				00 00 00 00 00 88 58 24 00 00 00 00 00 75 40 00
				00 00 00 0a 05 00 06 00 00 00 00 00 38 3d 3e 3f
				3a 3f 3f 3f 3f 05 05 05 05 0a 0a 0a 0a 00 00 00
				00 88 58 24 00 00 00 00 00 65 19 00 00 00 00 0a
				05 00 06 00 00 00 00 00 48 3a 3a 3a 3a 3a 3a 3a
				3a 00 00 00 00 00 00 00 00 00 00 00 00 f8 5a 24
				00 00 00 00 00 00 00 00 00 00 00 0a 0a 00 06 00
				00 00 00 00 58 3a 3a 3a 3a 3a 3a 3a 3a 00 00 00
				00 00 00 00 00 00 00 00 00 f8 5a 24 00 00 00 00
				00 03 00 00 01 0a 05 0f 46 40 00 00 03 00 44 06
				00 00 01 0a 08 0f 46 40 00 00 03 00 44 08 00 00
				01 0a 05 0f 46 40 00 00 03 00 44 0a 00 00 01 0a
				05 0f 46 40 00 00 03 00 44 0c 00 00 01 0a 08 0f
				46 40 00 00 03 00 44 10 08 0e 05 00 2c 04 04 d1
				84 00 00 00 00 0a 05 00 06 00 00 00 00 00 38 3d
				3e 3f 3a 00 00 00 00 05 05 05 05 00 00 00 00 00
				00 00 00 88 58 24 00 00 00 00 00 75 40 00 00 00
				00 0a 05 00 06 00 00 00 00 00 38 3d 3e 3f 3a 00
				00 00 00 05 05 05 05 00 00 00 00 00 00 00 00 88
				58 24 00 00 00 00 00 65 19 00 00 00 00 0a 05 00
				06 00 00 00 00 00 48 3a 3a 3a 3a 00 00 00 00 00
				00 00 00 00 00 00 00 00 00 00 00 f8 5a 24 00 00
				00 00 00 00 00 00 00 00 00 0a 0a 00 06 00 00 00
				00 00 58 3a 3a 3a 3a 00 00 00 00 00 00 00 00 00
				00 00 00 00 00 00 00 f8 5a 24 00 00 00 00 00 0c
				00 00 01 0a 05 0f 46 40 00 00 03 00 44 0d 00 00
				01 0a 08 0f 46 40 00 00 03 00 44 0e 00 00 01 0a
				05 0f 46 40 00 00 03 00 44 0f 01 00 01 0a 05 0f
				46 40 00 00 03 00 44 10 01 00 01 0a 08 0f 46 40
				00 00 03 00 44 10 08 0e 05 00 2c 04 04 d1 84 00
				00 00 00 0a 05 00 06 00 00 00 00 00 38 3d 3e 3f
				3a 00 00 00 00 05 05 05 05 00 00 00 00 00 00 00
				00 88 58 24 00 00 00 00 00 75 40 00 00 00 00 0a
				05 00 06 00 00 00 00 00 38 3d 3e 3f 3a 3f 3f 3f
				3f 05 05 05 05 05 05 05 05 00 00 00 00 88 58 24
				00 00 00 00 00 65 19 00 00 00 00 0a 05 00 06 00
				00 00 00 00 48 3a 3a 3a 3a 3a 3a 3a 3a 00 00 00
				00 00 00 00 00 00 00 00 00 f8 5a 24 00 00 00 00
				00 00 00 00 00 00 00 0a 0a 00 06 00 00 00 00 00
				58 3a 3a 3a 3a 3a 3a 3a 3a 00 00 00 00 00 00 00
				00 00 00 00 00 f8 5a 24 00 00 00 00 00 0c 01 00
				01 0a 05 0f 46 40 00 00 03 00 44 0d 01 00 01 0a
				08 0f 46 40 00 00 03 00 44 0e 02 00 01 0a 05 0f
				46 40 00 00 03 00 44 0f 02 00 01 0a 05 0f 46 40
				00 00 03 00 44 10 02 00 01 0a 08 0f 46 40 00 00
				03 00 44 10 08 0e 05 00 2c 04 04 d1 84 00 00 00
				00 0a 05 00 06 00 00 00 00 00 38 3d 3e 3f 3a 00
				00 00 00 05 05 05 05 00 00 00 00 00 00 00 00 88
				58 24 00 00 00 00 00 75 40 00 00 00 00 0a 05 00
				06 00 00 00 00 00 38 3d 3e 3f 3a 00 00 00 00 05
				05 05 05 00 00 00 00 00 00 00 00 88 58 24 00 00
				00 00 00 65 19 00 00 00 00 0a 05 00 06 00 00 00
				00 00 48 3a 3a 3a 3a 00 00 00 00 00 00 00 00 00
				00 00 00 00 00 00 00 f8 5a 24 00 00 00 00 00 00
				00 00 00 00 00 0a 0a 00 06 00 00 00 00 00 58 3a
				3a 3a 3a 00 00 00 00 00 00 00 00 00 00 00 00 00
				00 00 00 f8 5a 24 00 00 00 00 00 0c 00 00 01 0a
				05 0f 46 40 00 00 03 00 44 0d 00 00 01 0a 08 0f
				46 40 00 00 03 00 44 0e 00 00 01 0a 05 0f 46 40
				00 00 03 00 44 0f 01 00 01 0a 05 0f 46 40 00 00
				03 00 44 10 01 00 01 0a 08 0f 46 40 00 00 03 00
				44 10 08 0e 05 00 2c 04 04 d1 84 00 00 00 00 0a
				05 00 06 00 00 00 00 00 38 3d 3e 3f 3a 00 00 00
				00 05 05 05 05 00 00 00 00 00 00 00 00 88 58 24
				00 00 00 00 00 75 40 00 00 00 00 0a 05 00 06 00
				00 00 00 00 38 3d 3e 3f 3a 3f 3f 3f 3f 05 05 05
				05 08 08 08 08 00 00 00 00 88 58 24 00 00 00 00
				00 65 19 00 00 00 00 0a 05 00 06 00 00 00 00 00
				48 3a 3a 3a 3a 3a 3a 3a 3a 00 00 00 00 00 00 00
				00 00 00 00 00 f8 5a 24 00 00 00 00 00 00 00 00
				00 00 00 0a 0a 00 06 00 00 00 00 00 58 3a 3a 3a
				3a 3a 3a 3a 3a 00 00 00 00 00 00 00 00 00 00 00
				00 f8 5a 24 00 00 00 00 00 0c 01 00 01 0a 05 0f
				46 40 00 00 03 00 44 0d 01 00 01 0a 08 0f 46 40
				00 00 03 00 44 0e 02 00 01 0a 05 0f 46 40 00 00
				03 00 44 0f 02 00 01 0a 05 0f 46 40 00 00 03 00
				44 10 02 00 01 0a 08 0f 46 40 00 00 03 00 44 10
				08 0e 05 00 2c 04 04 d1 84 00 00 00 00 0a 05 00
				06 00 00 00 00 00 38 3d 3e 3f 3a 00 00 00 00 05
				05 05 05 00 00 00 00 00 00 00 00 88 58 24 00 00
				00 00 00 75 40 00 00 00 00 0a 05 00 06 00 00 00
				00 00 38 3d 3e 3f 3a 00 00 00 00 05 05 05 05 00
				00 00 00 00 00 00 00 88 58 24 00 00 00 00 00 65
				19 00 00 00 00 0a 05 00 06 00 00 00 00 00 48 3a
				3a 3a 3a 00 00 00 00 00 00 00 00 00 00 00 00 00
				00 00 00 f8 5a 24 00 00 00 00 00 00 00 00 00 00
				00 0a 0a 00 06 00 00 00 00 00 58 3a 3a 3a 3a 00
				00 00 00 00 00 00 00 00 00 00 00 00 00 00 00 f8
				5a 24 00 00 00 00 00 0c 00 00 01 0a 05 0f 46 40
				00 00 03 00 44 0d 00 00 01 0a 08 0f 46 40 00 00
				03 00 44 0e 00 00 01 0a 05 0f 46 40 00 00 03 00
				44 0f 01 00 01 0a 05 0f 46 40 00 00 03 00 44 10
				01 00 01 0a 08 0f 46 40 00 00 03 00 44 7a 14 c0
				61 40 01 00 c2 0d 74 05 00 6e 14 c0 61 40 ff ff
				bf ff 00 00 00 00 6e e4 c5 61 40 fe ff ff ff 00
				00 00 00 71 5b f5 19 71 5b 6f 17 5b 74 17 71 56
				00 ff 72 71 6e 0c c1 61 40 fe ff ff ff 00 00 00
				00 6e 40 65 61 80 fe ff ff ff 00 00 00 00 71 6e
				00 23 61 40 ff ff 80 fc 00 00 23 00 71 6e 00 23
				61 40 ff ff 80 fc 00 00 27 00 71 6e 00 23 61 40
				ff ff 80 fc 00 00 2b 00 71 6e 00 23 61 40 ff ff
				80 fc 00 00 2f 00 71 41 23 10 08 6a 18 cb bd dc
				4e 5c 08 00 00 00 00 00 00 ac 18 31 19 c1 00 00
				00 00 00 00 00 00 00 00 00 00 06 03 80 01 10 00
				60 04 02 03 80 01 10 00 02 04 2e 23 02 01 10 00
				02 00 2f 32 03 02 10 00 02 00 fe 40 04 00 00 00
				00 00 0f 00 00 00 00 00 00 00 0f 00 00 00 00 00
				00 00 0f 00 00 00 00 00 00 00 0f 00 00 00 00 00
				00 00 0f 00 00 00 00 00 00 00 0f 00 00 00 00 00
				00 00 0f 00 00 00 00 00 00 00 0f 00 00 00 00 00
				00 00 0f 00 00 00 00 00 00 00 0f 00 00 00 00 00
				00 00 0f 00 00 00 00 00 00 00 41 06 0f 04 02 0f
				06 00 00 10 ff 03 00 80 ff 03 00 80 ff 03 00 10
				ff 03 00 10 ff 03 00 10 ff 03 00 10 ff 03 00 10
				ff 03 00 10 ff 03 00 10 ff 03 00 00 ff 03 00 00
				ff 03 00 00 ff 03 00 00 ff 03 00 00 40 05 20 04
				01 ff 00 00 00 ff 00 00 00 ff 00 00 00 ff 00 00
				00 ff 00 00 00 ff 00 00 00 ff 00 00 00 ff 00 00
				00 ff 00 00 00 ff 00 00 00 ff 00 00 00 ff 00 00
				00 ff 00 00 00 ff 00 00 00 ff 00 00 00 ff 00 00
				00 ff 00 00 00 ff 00 00 00 ff 00 00 00 ff 00 00
				00 ff 00 00 00 ff 00 00 00 ff 00 00 00 ff 00 00
				00 ff 00 00 00 ff 00 00 00 ff 00 00 00 ff 00 00
				00 ff 00 00 00 ff 00 00 00 ff 00 00 00 ff 00 00
				00 40 05 10 04 00 46 10 00 00 ff 01 00 00 ff 02
				00 00 ff 03 00 00 ff 04 00 00 ff 00 00 00 ff 00
				00 00 ff 00 00 00 ff 00 00 00 ff 00 00 00 ff 00
				00 00 ff 00 00 00 ff 00 00 00 ff 00 00 00 ff 00
				00 00 ff 00 00 00 10 05 40 01 00 00 00 0b 03 00
				00 0a 02 00 00 08 02 00 20 04 02 00 80 00 00 00
				80 00 00 00 80 00 00 00 80 00 00 00 20 00 00 00
				20 00 03 00 00 0c 03 00 00 0a 03 00 80 0b 03 00
				80 0b 03 00 80 0b 03 00 80 0b 03 71 71 6e 14 c0
				61 40 ff ff 3f fa 00 00 c0 01 74 05 00 6e 14 c0
				61 40 f7 ff ff ff 08 00 00 00 6e b8 c1 61 40 ff
				ff 3f 81 00 03 00 08 6e 00 23 61 40 ff ff 83 fc
				00 00 00 00 71 58 40 c0 61 40 10 00 00 0a 1d 00
				00 0a 04 00 00 08 04 00 20 04 04 00 80 00 00 00
				80 00 00 00 80 00 00 00 80 00 00 00 20 00 00 00
				20 00 1d 00 00 0c 1d 00 00 0a 1d 00 80 0a 1d 00
				80 0a 1d 00 80 0a 1d 00 80 0a 1d 71 6e 00 23 61
				40 ff ff fc fc 00 00 02 03 71 7a 14 c0 61 40 14
				00 c2 0d 74 05 00 6e 14 c0 61 40 ff ff bf ff 00
				00 00 00 74 14 00 71 6e 14 c0 61 40 ff ff ff f2
				00 00 00 00 74 0a 00 6e 00 23 61 40 ff ff fc ff
				00 00 01 00 6e 0c c1 61 60 ff bf ff ff 00 40 00
				00 6e 14 c0 61 40 ff ff 7f ff 00 00 00 00 6e 30
				c1 61 60 f0 ff ff ff 0f 00 00 00 6e 34 c0 61 40
				ff ff ee 7f 00 00 00 80 56 17 ff 6e 0c c1 61 60
				fc ff ff ff 01 00 00 00 6e 30 c1 61 60 0f ff ff
				ff f0 00 00 00 74 0a 00 6e 30 c1 61 60 0f ff ff
				ff 00 00 00 00 6e 10 c1 61 40 e0 e0 e0 e0 00 00
				00 00 6e 2c c1 61 40 e0 e0 e0 e0 00 00 00 00 3a
				05 15 6e 40 c1 61 60 fd ff ff ff 02 00 00 00 98
				0a 01 00 00 01 fe 01 71 98 02 01 00 00 01 d0 00
				6e 10 c1 61 40 e0 e0 e0 e0 10 10 10 10 6e 2c c1
				61 40 e0 e0 e0 e0 10 10 10 10 71 5f 0c c1 61 60
				00 01 40 ff 40 00 00 00 00 40 65 61 80 fe bf 00
				bf 3a 00 03 5b 59 1b 72 71 3a 07 01 38 6e 40 c1
				61 60 fe ff ff ff 01 00 00 00 72 5b ad 1c 52 e8
				df 00 71 71 6e 0c c1 61 60 fe ff 00 ff 00 00 00
				00 6e 30 c1 61 40 f0 ff ff ff 00 00 00 00 6e b0
				c1 61 40 f0 ff ff ff 00 00 00 00 6e 34 c0 61 40
				ff ff ee 7f 00 00 11 80 56 17 ff 6e 14 c0 61 40
				ff ff 7f ff 00 00 80 00 6e 00 23 61 40 ff ff fc
				ff 00 00 02 00 74 05 00 6e 14 c0 61 40 ff ff ff
				f2 00 00 00 0d 74 05 00 6e 14 c0 61 40 ff ff bf
				ff 00 00 40 00 74 05 00 6e 14 c0 61 40 f7 ff ff
				ff 08 00 00 00 6e 0c c0 61 40 ff f0 f0 f0 00 03
				05 05 6e b8 c1 61 40 ff ff ff 81 00 03 00 08 6e
				00 23 61 40 ff ff 83 fc 00 00 00 00 6e 40 c1 61
				60 fe ff ff ff 00 00 00 00 71 6e 0c c1 61 60 fd
				ff ff ff 02 00 00 00 6e 30 c1 61 60 ff ff bf ff
				00 00 40 00 71 10 05 40 01 01 00 00 00 00 0a 10
				00 00 00 a0 40 00 00 80 40 00 00 80 40 00 00 80
				40 00 00 80 40 00 00 80 40 00 00 20 00 00 32 10
				80 00 0a 90 80 00 00 80 80 00 00 80 80 00 00 80
				80 00 00 80 80 00 00 80 80 00 71 71 6e 40 65 61
				80 fe ff ff ff 00 00 00 00 71 71 98 07 01 00 00
				01 ef 10 71 98 07 01 00 00 01 ef 00 71 58 40 c0
				61 40 10 00 00 00 00 32 10 00 00 00 a0 40 00 00
				80 40 00 00 80 40 00 00 80 40 00 00 80 40 00 00
				80 40 00 00 20 00 00 32 10 80 00 96 90 80 00 00
				80 80 00 00 80 80 00 00 80 80 00 00 80 80 00 00
				80 80 00 71 42 15 02 07 13 04 03 0a 04 28 23 28
				23 01 04 04 06 45 1c 00 00 00 00 00 00 00 00 00
				00 00 00 00 00 00 00 14 00 02 19 0a 03 1e 14 04
				2b 28 06 1e 00 03 25 0f 04 2f 21 06 28 00 04 32
				14 06 3c 00 06 14 00 02 19 0a 03 1e 14 04 2b 28
				06 1e 00 03 25 0f 04 2f 21 06 28 00 04 32 14 06
				3c 00 06 14 00 02 19 0a 03 1e 14 04 2b 28 06 1e
				00 03 25 0f 04 2f 21 06 28 00 04 32 14 06 3c 00
				06 0f 00 02 16 09 03 1d 0e 04 27 12 06 17 00 03
				21 09 04 27 0e 06 1f 00 04 27 09 06 27 00 06 a7
				1d 00 00 2f 1e 00 00 b7 1e 00 00 3f 1f 00 00 c7
				1f 00 00 4f 20 00 00 10 08 00 00 00 10 08 00 1e
				00 00 00 00 01 05 05 00 40 00 00 00 00 00 30 14
				00 00 00 00 01 05 05 00 40 00 00 00 00 00 30 10
				00 00 00 00 01 05 05 00 40 00 00 00 00 00 30 0c
				00 00 00 00 01 05 05 00 40 00 00 00 00 00 30 0a
				00 00 00 00 01 05 05 00 40 00 00 00 00 00 30 09
				00 00 00 00 01 05 05 00 40 00 00 00 00 00 30 08
				00 00 00 00 01 05 05 00 40 00 00 00 00 00 30 06
				00 00 00 00 01 05 05 00 40 00 00 00 00 00 30 10
				08 00 00 00 10 08 00 1e 00 00 00 00 00 05 05 00
				00 00 00 00 00 00 00 14 00 00 00 00 00 05 05 00
				00 00 00 00 00 00 00 10 00 00 00 00 03 00 01 00
				50 00 00 00 00 00 00 0c 00 00 00 00 03 00 01 00
				50 00 00 00 00 00 00 0a 00 00 00 00 00 05 05 00
				00 00 00 00 00 00 00 09 00 00 00 00 03 00 01 00
				40 00 00 00 00 00 00 08 00 00 00 00 03 00 01 00
				40 00 00 00 00 00 00 06 00 00 00 00 00 05 05 00
				00 00 00 00 00 00 00 10 08 00 00 00 10 08 00 1e
				00 00 00 00 00 05 05 00 00 00 00 00 00 00 00 14
				00 00 00 00 00 05 05 00 00 00 00 00 00 00 00 10
				00 00 00 00 03 00 01 00 50 00 00 00 00 00 00 0c
				00 00 00 00 03 00 01 00 50 00 00 00 00 00 00 0a
				00 00 00 00 00 05 05 00 00 00 00 00 00 00 00 09
				00 00 00 00 03 00 01 00 40 00 00 00 00 00 00 08
				00 00 00 00 03 00 01 00 40 00 00 00 00 00 00 06
				00 00 00 00 00 05 05 00 00 00 00 00 00 00 00 10
				08 00 00 00 10 08 00 1e 00 00 00 00 00 05 05 00
				00 00 00 00 00 00 00 14 00 00 00 00 00 05 05 00
				00 00 00 00 00 00 00 10 00 00 00 00 03 00 01 00
				50 00 00 00 00 00 00 0c 00 00 00 00 03 00 01 00
				50 00 00 00 00 00 00 0a 00 00 00 00 00 05 05 00
				00 00 00 00 00 00 00 09 00 00 00 00 03 00 01 00
				40 00 00 00 00 00 00 08 00 00 00 00 03 00 01 00
				40 00 00 00 00 00 00 06 00 00 00 00 00 05 05 00
				00 00 00 00 00 00 00 10 08 00 00 00 10 08 00 1e
				00 00 00 00 00 05 05 00 00 00 00 00 00 00 00 14
				00 00 00 00 00 05 05 00 00 00 00 00 00 00 00 10
				00 00 00 00 03 00 01 00 50 00 00 00 00 00 00 0c
				00 00 00 00 03 00 01 00 50 00 00 00 00 00 00 0a
				00 00 00 00 00 05 05 00 00 00 00 00 00 00 00 09
				00 00 00 00 03 00 01 00 40 00 00 00 00 00 00 08
				00 00 00 00 03 00 01 00 40 00 00 00 00 00 00 06
				00 00 00 00 00 05 05 00 00 00 00 00 00 00 00 10
				08 00 00 00 10 08 00 1e 00 00 00 00 00 05 05 00
				00 00 00 00 00 00 00 14 00 00 00 00 00 05 05 00
				00 00 00 00 00 00 00 10 00 00 00 00 03 00 01 00
				50 00 00 00 00 00 00 0c 00 00 00 00 03 00 01 00
				50 00 00 00 00 00 00 0a 00 00 00 00 00 05 05 00
				00 00 00 00 00 00 00 09 00 00 00 00 03 00 01 00
				40 00 00 00 00 00 00 08 00 00 00 00 03 00 01 00
				40 00 00 00 00 00 00 06 00 00 00 00 00 05 05 00
				00 00 00 00 00 00 00
			];

			/* nvdisplay RM requires this child at probe or it bails
			 * with "no nvdisplay-niso child node" -> no crtc/format.
			 * Mirrors NVIDIA's tegra234 display node (dummy niso). */
			/* Stock identity + coherency for the NISO DMA child; iommus
			 * intentionally omitted (no guest IOMMU -- the host SMMU
			 * phandle must not be copied). The previous
			 * "nvidia,nvidia,dummy" + empty iommus form made
			 * of_dma_configure() set the NISO DMA device NON-coherent
			 * while nvkms allocates NISO surfaces WRITE_BACK assuming
			 * IO-coherence. */
			nvdisplay-niso {
				compatible = "nvidia,tegra234-display-niso";
				dma-coherent;
			};
		};
	};

	// We need to keep fuse here disabled without passing through in order
	// the display works.
	fuse@3810000 {
		compatible = "nvidia,tegra234-efuse";
		reg = <0x0 0x03810000 0x0 0x10000>;
		clocks = <&bpmp TEGRA234_CLK_FUSE>;
		clock-names = "fuse";
		status = "disabled";
	};


	tegra_icc: icc {
		#interconnect-cells = <1>;
		clocks = <&bpmp TEGRA234_CLK_EMC>;
		clock-names = "emc";
		compatible = "nvidia,tegra23x-icc";
		nvidia,bpmp = <&bpmp>;
		status = "okay";
	};


	// Define the carveouts regions for the carveouts driver (no
	// vidmem_reserved: that carveout is GPU-only, dropped for disp-vm).
	tegra-carveouts {
		compatible = "nvidia,carveouts";
		memory-region = <&generic_reserved &vpr &fsi_reserved>;
		status = "okay";
	};

	fw-cfg@9020000 {
		dma-coherent;
		reg = <0x00 0x9020000 0x00 0x18>;
		compatible = "qemu,fw-cfg-mmio";
	};

	virtio_mmio@a000000 {
		dma-coherent;
		interrupts = <0x00 0x10 0x01>;
		reg = <0x00 0xa000000 0x00 0x200>;
		compatible = "virtio,mmio";
	};

	virtio_mmio@a000200 {
		dma-coherent;
		interrupts = <0x00 0x11 0x01>;
		reg = <0x00 0xa000200 0x00 0x200>;
		compatible = "virtio,mmio";
	};

	virtio_mmio@a000400 {
		dma-coherent;
		interrupts = <0x00 0x12 0x01>;
		reg = <0x00 0xa000400 0x00 0x200>;
		compatible = "virtio,mmio";
	};

	virtio_mmio@a000600 {
		dma-coherent;
		interrupts = <0x00 0x13 0x01>;
		reg = <0x00 0xa000600 0x00 0x200>;
		compatible = "virtio,mmio";
	};

	virtio_mmio@a000800 {
		dma-coherent;
		interrupts = <0x00 0x14 0x01>;
		reg = <0x00 0xa000800 0x00 0x200>;
		compatible = "virtio,mmio";
	};

	virtio_mmio@a000a00 {
		dma-coherent;
		interrupts = <0x00 0x15 0x01>;
		reg = <0x00 0xa000a00 0x00 0x200>;
		compatible = "virtio,mmio";
	};

	virtio_mmio@a000c00 {
		dma-coherent;
		interrupts = <0x00 0x16 0x01>;
		reg = <0x00 0xa000c00 0x00 0x200>;
		compatible = "virtio,mmio";
	};

	virtio_mmio@a000e00 {
		dma-coherent;
		interrupts = <0x00 0x17 0x01>;
		reg = <0x00 0xa000e00 0x00 0x200>;
		compatible = "virtio,mmio";
	};

	virtio_mmio@a001000 {
		dma-coherent;
		interrupts = <0x00 0x18 0x01>;
		reg = <0x00 0xa001000 0x00 0x200>;
		compatible = "virtio,mmio";
	};

	virtio_mmio@a001200 {
		dma-coherent;
		interrupts = <0x00 0x19 0x01>;
		reg = <0x00 0xa001200 0x00 0x200>;
		compatible = "virtio,mmio";
	};

	virtio_mmio@a001400 {
		dma-coherent;
		interrupts = <0x00 0x1a 0x01>;
		reg = <0x00 0xa001400 0x00 0x200>;
		compatible = "virtio,mmio";
	};

	virtio_mmio@a001600 {
		dma-coherent;
		interrupts = <0x00 0x1b 0x01>;
		reg = <0x00 0xa001600 0x00 0x200>;
		compatible = "virtio,mmio";
	};

	virtio_mmio@a001800 {
		dma-coherent;
		interrupts = <0x00 0x1c 0x01>;
		reg = <0x00 0xa001800 0x00 0x200>;
		compatible = "virtio,mmio";
	};

	virtio_mmio@a001a00 {
		dma-coherent;
		interrupts = <0x00 0x1d 0x01>;
		reg = <0x00 0xa001a00 0x00 0x200>;
		compatible = "virtio,mmio";
	};

	virtio_mmio@a001c00 {
		dma-coherent;
		interrupts = <0x00 0x1e 0x01>;
		reg = <0x00 0xa001c00 0x00 0x200>;
		compatible = "virtio,mmio";
	};

	virtio_mmio@a001e00 {
		dma-coherent;
		interrupts = <0x00 0x1f 0x01>;
		reg = <0x00 0xa001e00 0x00 0x200>;
		compatible = "virtio,mmio";
	};

	virtio_mmio@a002000 {
		dma-coherent;
		interrupts = <0x00 0x20 0x01>;
		reg = <0x00 0xa002000 0x00 0x200>;
		compatible = "virtio,mmio";
	};

	virtio_mmio@a002200 {
		dma-coherent;
		interrupts = <0x00 0x21 0x01>;
		reg = <0x00 0xa002200 0x00 0x200>;
		compatible = "virtio,mmio";
	};

	virtio_mmio@a002400 {
		dma-coherent;
		interrupts = <0x00 0x22 0x01>;
		reg = <0x00 0xa002400 0x00 0x200>;
		compatible = "virtio,mmio";
	};

	virtio_mmio@a002600 {
		dma-coherent;
		interrupts = <0x00 0x23 0x01>;
		reg = <0x00 0xa002600 0x00 0x200>;
		compatible = "virtio,mmio";
	};

	virtio_mmio@a002800 {
		dma-coherent;
		interrupts = <0x00 0x24 0x01>;
		reg = <0x00 0xa002800 0x00 0x200>;
		compatible = "virtio,mmio";
	};

	virtio_mmio@a002a00 {
		dma-coherent;
		interrupts = <0x00 0x25 0x01>;
		reg = <0x00 0xa002a00 0x00 0x200>;
		compatible = "virtio,mmio";
	};

	virtio_mmio@a002c00 {
		dma-coherent;
		interrupts = <0x00 0x26 0x01>;
		reg = <0x00 0xa002c00 0x00 0x200>;
		compatible = "virtio,mmio";
	};

	virtio_mmio@a002e00 {
		dma-coherent;
		interrupts = <0x00 0x27 0x01>;
		reg = <0x00 0xa002e00 0x00 0x200>;
		compatible = "virtio,mmio";
	};

	virtio_mmio@a003000 {
		dma-coherent;
		interrupts = <0x00 0x28 0x01>;
		reg = <0x00 0xa003000 0x00 0x200>;
		compatible = "virtio,mmio";
	};

	virtio_mmio@a003200 {
		dma-coherent;
		interrupts = <0x00 0x29 0x01>;
		reg = <0x00 0xa003200 0x00 0x200>;
		compatible = "virtio,mmio";
	};

	virtio_mmio@a003400 {
		dma-coherent;
		interrupts = <0x00 0x2a 0x01>;
		reg = <0x00 0xa003400 0x00 0x200>;
		compatible = "virtio,mmio";
	};

	virtio_mmio@a003600 {
		dma-coherent;
		interrupts = <0x00 0x2b 0x01>;
		reg = <0x00 0xa003600 0x00 0x200>;
		compatible = "virtio,mmio";
	};

	virtio_mmio@a003800 {
		dma-coherent;
		interrupts = <0x00 0x2c 0x01>;
		reg = <0x00 0xa003800 0x00 0x200>;
		compatible = "virtio,mmio";
	};

	virtio_mmio@a003a00 {
		dma-coherent;
		interrupts = <0x00 0x2d 0x01>;
		reg = <0x00 0xa003a00 0x00 0x200>;
		compatible = "virtio,mmio";
	};

	virtio_mmio@a003c00 {
		dma-coherent;
		interrupts = <0x00 0x2e 0x01>;
		reg = <0x00 0xa003c00 0x00 0x200>;
		compatible = "virtio,mmio";
	};

	virtio_mmio@a003e00 {
		dma-coherent;
		interrupts = <0x00 0x2f 0x01>;
		reg = <0x00 0xa003e00 0x00 0x200>;
		compatible = "virtio,mmio";
	};

	gpio-keys {
		compatible = "gpio-keys";

		poweroff {
			gpios = <0x8007 0x03 0x00>;
			linux,code = <0x74>;
			label = "GPIO Key Poweroff";
		};
	};

	pl061@9030000 {
		phandle = <0x8007>;
		clock-names = "apb_pclk";
		clocks = <0x8000>;
		interrupts = <0x00 0x07 0x04>;
		gpio-controller;
		#gpio-cells = <0x02>;
		compatible = "arm,pl061\0arm,primecell";
		reg = <0x00 0x9030000 0x00 0x1000>;
	};

	pcie@10000000 {
		interrupt-map-mask = <0x1800 0x00 0x00 0x07>;
		interrupt-map = <0x00 0x00 0x00 0x01 0x8005 0x00 0x00 0x00 0x03 0x04 0x00 0x00 0x00 0x02 0x8005 0x00 0x00 0x00 0x04 0x04 0x00 0x00 0x00 0x03 0x8005 0x00 0x00 0x00 0x05 0x04 0x00 0x00 0x00 0x04 0x8005 0x00 0x00 0x00 0x06 0x04 0x800 0x00 0x00 0x01 0x8005 0x00 0x00 0x00 0x04 0x04 0x800 0x00 0x00 0x02 0x8005 0x00 0x00 0x00 0x05 0x04 0x800 0x00 0x00 0x03 0x8005 0x00 0x00 0x00 0x06 0x04 0x800 0x00 0x00 0x04 0x8005 0x00 0x00 0x00 0x03 0x04 0x1000 0x00 0x00 0x01 0x8005 0x00 0x00 0x00 0x05 0x04 0x1000 0x00 0x00 0x02 0x8005 0x00 0x00 0x00 0x06 0x04 0x1000 0x00 0x00 0x03 0x8005 0x00 0x00 0x00 0x03 0x04 0x1000 0x00 0x00 0x04 0x8005 0x00 0x00 0x00 0x04 0x04 0x1800 0x00 0x00 0x01 0x8005 0x00 0x00 0x00 0x06 0x04 0x1800 0x00 0x00 0x02 0x8005 0x00 0x00 0x00 0x03 0x04 0x1800 0x00 0x00 0x03 0x8005 0x00 0x00 0x00 0x04 0x04 0x1800 0x00 0x00 0x04 0x8005 0x00 0x00 0x00 0x05 0x04>;
		#interrupt-cells = <0x01>;
		ranges = <0x1000000 0x00 0x00 0x00 0x3eff0000 0x00 0x10000 0x2000000 0x00 0x10000000 0x00 0x10000000 0x00 0x2eff0000 0x3000000 0x80 0x00 0x80 0x00 0x80 0x00>;
		reg = <0x5f 0xd0000000 0x00 0x10000000>;
		msi-map = <0x00 0x8006 0x00 0x10000>;
		dma-coherent;
		bus-range = <0x00 0xff>;
		linux,pci-domain = <0x00>;
		#size-cells = <0x02>;
		#address-cells = <0x03>;
		device_type = "pci";
		compatible = "pci-host-ecam-generic";
	};

	pl031@9010000 {
		clock-names = "apb_pclk";
		clocks = <0x8000>;
		interrupts = <0x00 0x02 0x04>;
		reg = <0x00 0x9010000 0x00 0x1000>;
		compatible = "arm,pl031\0arm,primecell";
	};

	pl011@9000000 {
		clock-names = "uartclk\0apb_pclk";
		clocks = <0x8000 0x8000>;
		interrupts = <0x00 0x01 0x04>;
		reg = <0x00 0x9000000 0x00 0x1000>;
		compatible = "arm,pl011\0arm,primecell";
	};

	pmu {
		interrupts = <0x01 0x07 0x04>;
		compatible = "arm,armv8-pmuv3";
	};

	intc@8000000 {
		phandle = <0x8005>;
		reg = <0x00 0x8000000 0x00 0x10000 0x00 0x80a0000 0x00 0xf60000>;
		#redistributor-regions = <0x01>;
		compatible = "arm,gic-v3";
		ranges;
		#size-cells = <0x02>;
		#address-cells = <0x02>;
		interrupt-controller;
		#interrupt-cells = <0x03>;

		its@8080000 {
			phandle = <0x8006>;
			reg = <0x00 0x8080000 0x00 0x20000>;
			#msi-cells = <0x01>;
			msi-controller;
			compatible = "arm,gic-v3-its";
		};
	};

	flash@0 {
		bank-width = <0x04>;
		reg = <0x00 0x00 0x00 0x4000000 0x00 0x4000000 0x00 0x4000000>;
		compatible = "cfi-flash";
	};

	cpus {
		#size-cells = <0x00>;
		#address-cells = <0x01>;

		cpu-map {

			socket0 {

				cluster0 {

					core0 {
						cpu = <0x8004>;
					};

					core1 {
						cpu = <0x8003>;
					};

					core2 {
						cpu = <0x8002>;
					};

					core3 {
						cpu = <0x8001>;
					};
				};
			};
		};

		cpu@0 {
			phandle = <0x8004>;
			reg = <0x00>;
			enable-method = "psci";
			compatible = "arm,arm-v8";
			device_type = "cpu";
		};

		cpu@1 {
			phandle = <0x8003>;
			reg = <0x01>;
			enable-method = "psci";
			compatible = "arm,arm-v8";
			device_type = "cpu";
		};

		cpu@2 {
			phandle = <0x8002>;
			reg = <0x02>;
			enable-method = "psci";
			compatible = "arm,arm-v8";
			device_type = "cpu";
		};

		cpu@3 {
			phandle = <0x8001>;
			reg = <0x03>;
			enable-method = "psci";
			compatible = "arm,arm-v8";
			device_type = "cpu";
		};
	};

	timer {
		interrupts = <0x01 0x0d 0x04 0x01 0x0e 0x04 0x01 0x0b 0x04 0x01 0x0a 0x04>;
		always-on;
		compatible = "arm,armv8-timer\0arm,armv7-timer";
	};

	apb-pclk {
		phandle = <0x8000>;
		clock-output-names = "clk24mhz";
		clock-frequency = <0x16e3600>;
		#clock-cells = <0x00>;
		compatible = "fixed-clock";
	};

	chosen {
		bootargs = "rootwait root=/dev/vda console=ttyAMA0";
		stdout-path = "/pl011@9000000";
		rng-seed = <0x67b6f34f 0xc86e63c5 0xa358bcaa 0x4433845d 0xe55d22f3 0xbf39d920 0x8fd3366d 0x15f35a5b>;
		kaslr-seed = <0xca4d66e8 0xda2a6750>;
		#address-cells = <1>;
		#size-cells = <1>;
	};
};
